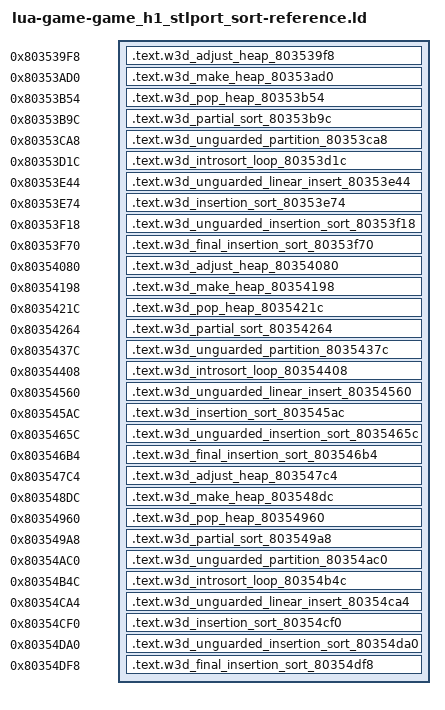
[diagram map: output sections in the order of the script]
/* Generated reference-only placements. All bodies are source-built. */
OUTPUT_FORMAT("elf32-powerpc")
OUTPUT_ARCH(powerpc)
ENTRY(w3d_adjust_heap_803539f8)
_SDA_BASE_ = 0x804b2540;
_SDA2_BASE_ = 0x804c2540;
memmove = 0x802eeef4;
w3d_stl_forward_80353c78 = 0x80353c78;
w3d_stl_forward_8035434c = 0x8035434c;
w3d_stl_forward_80354a90 = 0x80354a90;
SECTIONS {
  .text.w3d_adjust_heap_803539f8 0x803539f8 : { *(.text.w3d_adjust_heap_803539f8) }
  .text.w3d_make_heap_80353ad0 0x80353ad0 : { *(.text.w3d_make_heap_80353ad0) }
  .text.w3d_pop_heap_80353b54 0x80353b54 : { *(.text.w3d_pop_heap_80353b54) }
  .text.w3d_partial_sort_80353b9c 0x80353b9c : { *(.text.w3d_partial_sort_80353b9c) }
  .text.w3d_unguarded_partition_80353ca8 0x80353ca8 : { *(.text.w3d_unguarded_partition_80353ca8) }
  .text.w3d_introsort_loop_80353d1c 0x80353d1c : { *(.text.w3d_introsort_loop_80353d1c) }
  .text.w3d_unguarded_linear_insert_80353e44 0x80353e44 : { *(.text.w3d_unguarded_linear_insert_80353e44) }
  .text.w3d_insertion_sort_80353e74 0x80353e74 : { *(.text.w3d_insertion_sort_80353e74) }
  .text.w3d_unguarded_insertion_sort_80353f18 0x80353f18 : { *(.text.w3d_unguarded_insertion_sort_80353f18) }
  .text.w3d_final_insertion_sort_80353f70 0x80353f70 : { *(.text.w3d_final_insertion_sort_80353f70) }
  .text.w3d_adjust_heap_80354080 0x80354080 : { *(.text.w3d_adjust_heap_80354080) }
  .text.w3d_make_heap_80354198 0x80354198 : { *(.text.w3d_make_heap_80354198) }
  .text.w3d_pop_heap_8035421c 0x8035421c : { *(.text.w3d_pop_heap_8035421c) }
  .text.w3d_partial_sort_80354264 0x80354264 : { *(.text.w3d_partial_sort_80354264) }
  .text.w3d_unguarded_partition_8035437c 0x8035437c : { *(.text.w3d_unguarded_partition_8035437c) }
  .text.w3d_introsort_loop_80354408 0x80354408 : { *(.text.w3d_introsort_loop_80354408) }
  .text.w3d_unguarded_linear_insert_80354560 0x80354560 : { *(.text.w3d_unguarded_linear_insert_80354560) }
  .text.w3d_insertion_sort_803545ac 0x803545ac : { *(.text.w3d_insertion_sort_803545ac) }
  .text.w3d_unguarded_insertion_sort_8035465c 0x8035465c : { *(.text.w3d_unguarded_insertion_sort_8035465c) }
  .text.w3d_final_insertion_sort_803546b4 0x803546b4 : { *(.text.w3d_final_insertion_sort_803546b4) }
  .text.w3d_adjust_heap_803547c4 0x803547c4 : { *(.text.w3d_adjust_heap_803547c4) }
  .text.w3d_make_heap_803548dc 0x803548dc : { *(.text.w3d_make_heap_803548dc) }
  .text.w3d_pop_heap_80354960 0x80354960 : { *(.text.w3d_pop_heap_80354960) }
  .text.w3d_partial_sort_803549a8 0x803549a8 : { *(.text.w3d_partial_sort_803549a8) }
  .text.w3d_unguarded_partition_80354ac0 0x80354ac0 : { *(.text.w3d_unguarded_partition_80354ac0) }
  .text.w3d_introsort_loop_80354b4c 0x80354b4c : { *(.text.w3d_introsort_loop_80354b4c) }
  .text.w3d_unguarded_linear_insert_80354ca4 0x80354ca4 : { *(.text.w3d_unguarded_linear_insert_80354ca4) }
  .text.w3d_insertion_sort_80354cf0 0x80354cf0 : { *(.text.w3d_insertion_sort_80354cf0) }
  .text.w3d_unguarded_insertion_sort_80354da0 0x80354da0 : { *(.text.w3d_unguarded_insertion_sort_80354da0) }
  .text.w3d_final_insertion_sort_80354df8 0x80354df8 : { *(.text.w3d_final_insertion_sort_80354df8) }
  /DISCARD/ : { *(.text*) *(.rodata*) *(.data*) *(.bss*) *(.sdata*) *(.sbss*) *(.comment) }
}
